AUTOSAR XML (schema 4-0-3)
standard types defined: Boolean, UInt32
package /AUTOSAR_Platform/DataConstrs
  range DC_Boolean: raw 0..1
package /PATAC/MSM/ComponentTypes
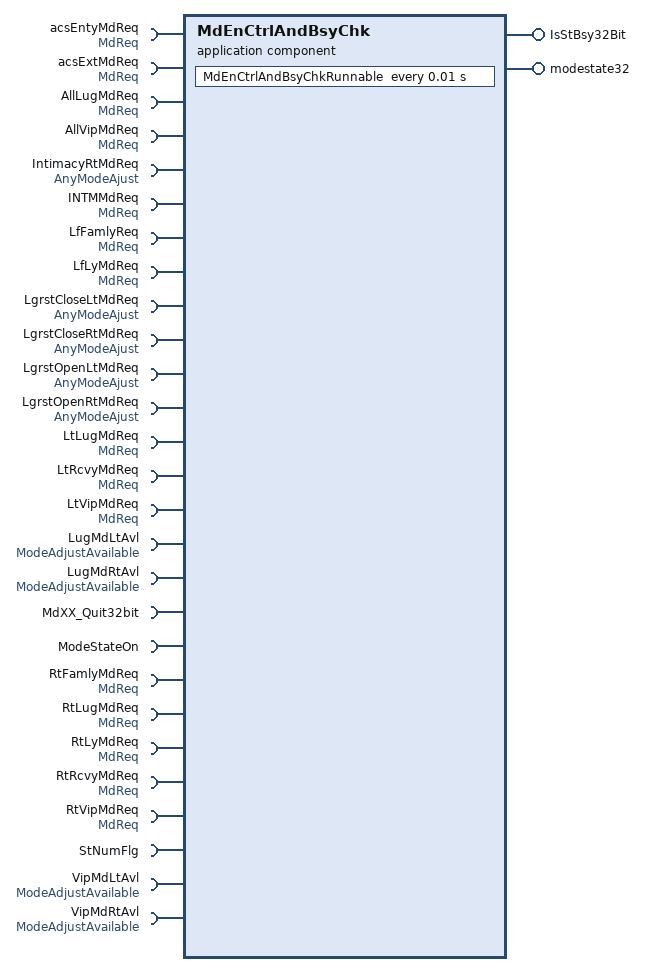
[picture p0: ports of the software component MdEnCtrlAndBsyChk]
  application sw component type MdEnCtrlAndBsyChk
    provide port IsStBsy32Bit: nonqueued-sender-com-spec{data-element=IsStBsy32Bit/Val, init-value=0}, provided-interface=IsStBsy32Bit
    provide port modestate32: nonqueued-sender-com-spec{data-element=modestate32/Val, init-value=0}, provided-interface=modestate32
    27 x require port:
      acsEntyMdReq: nonqueued-receiver-com-spec{data-element=MdReq/Val, filter=data-filter-type=ALWAYS, init-value=0}, required-interface=MdReq
      acsExtMdReq: nonqueued-receiver-com-spec{data-element=MdReq/Val, filter=data-filter-type=ALWAYS, init-value=0}, required-interface=MdReq
      AllLugMdReq: nonqueued-receiver-com-spec{data-element=MdReq/Val, filter=data-filter-type=ALWAYS, init-value=0}, required-interface=MdReq
      AllVipMdReq: nonqueued-receiver-com-spec{data-element=MdReq/Val, filter=data-filter-type=ALWAYS, init-value=0}, required-interface=MdReq
      IntimacyRtMdReq: nonqueued-receiver-com-spec{data-element=AnyModeAjust/Val, filter=data-filter-type=ALWAYS, init-value=0}, required-interface=AnyModeAjust
      INTMMdReq: nonqueued-receiver-com-spec{data-element=MdReq/Val, filter=data-filter-type=ALWAYS, init-value=0}, required-interface=MdReq
      LfFamlyReq: nonqueued-receiver-com-spec{data-element=MdReq/Val, filter=data-filter-type=ALWAYS, init-value=0}, required-interface=MdReq
      LfLyMdReq: nonqueued-receiver-com-spec{data-element=MdReq/Val, filter=data-filter-type=ALWAYS, init-value=0}, required-interface=MdReq
      LgrstCloseLtMdReq: nonqueued-receiver-com-spec{data-element=AnyModeAjust/Val, filter=data-filter-type=ALWAYS, init-value=0}, required-interface=AnyModeAjust
      LgrstCloseRtMdReq: nonqueued-receiver-com-spec{data-element=AnyModeAjust/Val, filter=data-filter-type=ALWAYS, init-value=0}, required-interface=AnyModeAjust
      LgrstOpenLtMdReq: nonqueued-receiver-com-spec{data-element=AnyModeAjust/Val, filter=data-filter-type=ALWAYS, init-value=0}, required-interface=AnyModeAjust
      LgrstOpenRtMdReq: nonqueued-receiver-com-spec{data-element=AnyModeAjust/Val, filter=data-filter-type=ALWAYS, init-value=0}, required-interface=AnyModeAjust
      LtLugMdReq: nonqueued-receiver-com-spec{data-element=MdReq/Val, filter=data-filter-type=ALWAYS, init-value=0}, required-interface=MdReq
      LtRcvyMdReq: nonqueued-receiver-com-spec{data-element=MdReq/Val, filter=data-filter-type=ALWAYS, init-value=0}, required-interface=MdReq
      LtVipMdReq: nonqueued-receiver-com-spec{data-element=MdReq/Val, filter=data-filter-type=ALWAYS, init-value=0}, required-interface=MdReq
      LugMdLtAvl: nonqueued-receiver-com-spec{data-element=ModeAdjustAvailable/Val, filter=data-filter-type=ALWAYS, init-value=0}, required-interface=ModeAdjustAvailable
      LugMdRtAvl: nonqueued-receiver-com-spec{data-element=ModeAdjustAvailable/Val, filter=data-filter-type=ALWAYS, init-value=0}, required-interface=ModeAdjustAvailable
      MdXX_Quit32bit: nonqueued-receiver-com-spec{data-element=MdXX_Quit32bit/Val, filter=data-filter-type=ALWAYS, init-value=0}, required-interface=MdXX_Quit32bit
      ModeStateOn: nonqueued-receiver-com-spec{data-element=ModeStateOn/Val, filter=data-filter-type=ALWAYS, init-value=0}, required-interface=ModeStateOn
      RtFamlyMdReq: nonqueued-receiver-com-spec{data-element=MdReq/Val, filter=data-filter-type=ALWAYS, init-value=0}, required-interface=MdReq
      RtLugMdReq: nonqueued-receiver-com-spec{data-element=MdReq/Val, filter=data-filter-type=ALWAYS, init-value=0}, required-interface=MdReq
      RtLyMdReq: nonqueued-receiver-com-spec{data-element=MdReq/Val, filter=data-filter-type=ALWAYS, init-value=0}, required-interface=MdReq
      RtRcvyMdReq: nonqueued-receiver-com-spec{data-element=MdReq/Val, filter=data-filter-type=ALWAYS, init-value=0}, required-interface=MdReq
      RtVipMdReq: nonqueued-receiver-com-spec{data-element=MdReq/Val, filter=data-filter-type=ALWAYS, init-value=0}, required-interface=MdReq
      StNumFlg: required-interface=StNumFlg
        required-com-specs:
          data-element=Is4s, filter=data-filter-type=ALWAYS, init-value=0
          data-element=Is6s, filter=data-filter-type=ALWAYS, init-value=0
          data-element=Is6s7s, filter=data-filter-type=ALWAYS, init-value=0
          data-element=Is7s, filter=data-filter-type=ALWAYS, init-value=0
      VipMdLtAvl: nonqueued-receiver-com-spec{data-element=ModeAdjustAvailable/Val, filter=data-filter-type=ALWAYS, init-value=0}, required-interface=ModeAdjustAvailable
      VipMdRtAvl: nonqueued-receiver-com-spec{data-element=ModeAdjustAvailable/Val, filter=data-filter-type=ALWAYS, init-value=0}, required-interface=ModeAdjustAvailable
    behavior MdEnCtrlAndBsyChk_InternalBehavior
      timing event TMT_EZEStateCtrlRunnable: start-on-event=MdEnCtrlAndBsyChkRunnable, period=0.01
      runnable MdEnCtrlAndBsyChkRunnable
        data-receive-point-by-arguments:
          30 x access:
            REC_acsEntyMdReq_Val: accessed-variable=acsEntyMdReq.Val
            REC_acsExtMdReq_Val: accessed-variable=acsExtMdReq.Val
            REC_AllLugMdReq_Val: accessed-variable=AllLugMdReq.Val
            REC_AllVipMdReq_Val: accessed-variable=AllVipMdReq.Val
            REC_IntimacyRtMdReq_Val: accessed-variable=IntimacyRtMdReq.Val
            REC_INTMMdReq_Val: accessed-variable=INTMMdReq.Val
            REC_LfFamlyReq_Val: accessed-variable=LfFamlyReq.Val
            REC_LfLyMdReq_Val: accessed-variable=LfLyMdReq.Val
            REC_LgrstCloseLtMdReq_Val: accessed-variable=LgrstCloseLtMdReq.Val
            REC_LgrstCloseRtMdReq_Val: accessed-variable=LgrstCloseRtMdReq.Val
            REC_LgrstOpenLtMdReq_Val: accessed-variable=LgrstOpenLtMdReq.Val
            REC_LgrstOpenRtMdReq_Val: accessed-variable=LgrstOpenRtMdReq.Val
            REC_LtLugMdReq_Val: accessed-variable=LtLugMdReq.Val
            REC_LtRcvyMdReq_Val: accessed-variable=LtRcvyMdReq.Val
            REC_LtVipMdReq_Val: accessed-variable=LtVipMdReq.Val
            REC_LugMdLtAvl_Val: accessed-variable=LugMdLtAvl.Val
            REC_LugMdRtAvl_Val: accessed-variable=LugMdRtAvl.Val
            REC_MdXX_Quit32bit_Val: accessed-variable=MdXX_Quit32bit.Val
            REC_ModeStateOn_Val: accessed-variable=ModeStateOn.Val
            REC_RtFamlyMdReq_Val: accessed-variable=RtFamlyMdReq.Val
            REC_RtLugMdReq_Val: accessed-variable=RtLugMdReq.Val
            REC_RtLyMdReq_Val: accessed-variable=RtLyMdReq.Val
            REC_RtRcvyMdReq_Val: accessed-variable=RtRcvyMdReq.Val
            REC_RtVipMdReq_Val: accessed-variable=RtVipMdReq.Val
            REC_StNumFlg_Is4s: accessed-variable=StNumFlg.Is4s
            REC_StNumFlg_Is6s: accessed-variable=StNumFlg.Is6s
            REC_StNumFlg_Is6s7s: accessed-variable=StNumFlg.Is6s7s
            REC_StNumFlg_Is7s: accessed-variable=StNumFlg.Is7s
            REC_VipMdLtAvl_Val: accessed-variable=VipMdLtAvl.Val
            REC_VipMdRtAvl_Val: accessed-variable=VipMdRtAvl.Val
        data-send-points:
          access SEND_IsStBsy32Bit_Val: accessed-variable=IsStBsy32Bit.Val
          access SEND_modestate32_Val: accessed-variable=modestate32.Val
  swc implementation MdEnCtrlAndBsyChk_Implementation: behavior=MdEnCtrlAndBsyChk_InternalBehavior
    code-descriptors:
      code Default: artifact-descriptors=autosar-engineering-object={short-label=Default, category=SWSRC}
package /PATAC/MSM/ModeAdjust/PortInterface
  8 x sender receiver interface:
    AnyModeAjust: invalidation-policy{data-element=AnyModeAjust/Val, handle-invalid=DONT-INVALIDATE}
      data Val: type=Boolean
    IsStBsy32Bit: invalidation-policy{data-element=IsStBsy32Bit/Val, handle-invalid=DONT-INVALIDATE}
      data Val: type=UInt32
    MdReq: invalidation-policy{data-element=MdReq/Val, handle-invalid=DONT-INVALIDATE}
      data Val: type=Boolean
    MdXX_Quit32bit: invalidation-policy{data-element=MdXX_Quit32bit/Val, handle-invalid=DONT-INVALIDATE}
      data Val: type=UInt32
    ModeAdjustAvailable: invalidation-policy{data-element=ModeAdjustAvailable/Val, handle-invalid=DONT-INVALIDATE}
      data Val: type=Boolean
    modestate32: invalidation-policy{data-element=modestate32/Val, handle-invalid=DONT-INVALIDATE}
      data Val: type=UInt32
    ModeStateOn: invalidation-policy{data-element=ModeStateOn/Val, handle-invalid=DONT-INVALIDATE}
      data Val: type=Boolean
    StNumFlg
      4 x data, all with type=Boolean:
        Is4s
        Is6s
        Is6s7s
        Is7s
      invalidation-policys:
        data-element=Is7s, handle-invalid=DONT-INVALIDATE
        data-element=Is6s, handle-invalid=DONT-INVALIDATE
        data-element=Is4s, handle-invalid=DONT-INVALIDATE
        data-element=Is6s7s, handle-invalid=DONT-INVALIDATE
